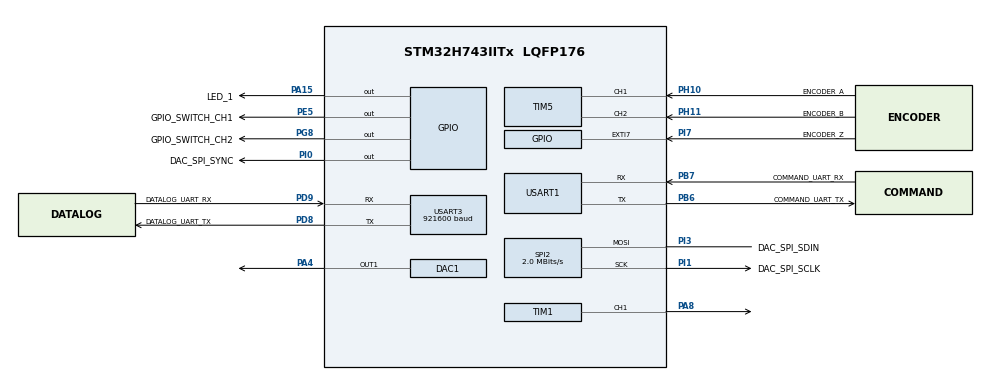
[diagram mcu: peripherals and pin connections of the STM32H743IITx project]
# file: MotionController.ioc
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CORTEX_M7.default_mode_Activation=1
DAC1.DAC_Channel-DAC_OUT1=DAC_CHANNEL_1
Dma.Request0=USART1_TX
Dma.Request1=USART1_RX
Dma.Request2=USART3_TX
Dma.USART1_RX.1.Direction=DMA_PERIPH_TO_MEMORY
Dma.USART1_RX.1.EventEnable=DISABLE
Dma.USART1_RX.1.FIFOMode=DMA_FIFOMODE_DISABLE
Dma.USART1_RX.1.Instance=DMA1_Stream1
Dma.USART1_RX.1.MemDataAlignment=DMA_MDATAALIGN_BYTE
Dma.USART1_RX.1.MemInc=DMA_MINC_ENABLE
Dma.USART1_RX.1.Mode=DMA_NORMAL
Dma.USART1_RX.1.PeriphDataAlignment=DMA_PDATAALIGN_BYTE
Dma.USART1_RX.1.PeriphInc=DMA_PINC_DISABLE
Dma.USART1_RX.1.Polarity=HAL_DMAMUX_REQ_GEN_RISING
Dma.USART1_RX.1.Priority=DMA_PRIORITY_LOW
Dma.USART1_RX.1.RequestNumber=1
Dma.USART1_RX.1.SignalID=NONE
Dma.USART1_RX.1.SyncEnable=DISABLE
Dma.USART1_RX.1.SyncPolarity=HAL_DMAMUX_SYNC_NO_EVENT
Dma.USART1_RX.1.SyncRequestNumber=1
Dma.USART1_RX.1.SyncSignalID=NONE
Dma.USART1_TX.0.Direction=DMA_MEMORY_TO_PERIPH
Dma.USART1_TX.0.EventEnable=DISABLE
Dma.USART1_TX.0.FIFOMode=DMA_FIFOMODE_DISABLE
Dma.USART1_TX.0.Instance=DMA1_Stream0
Dma.USART1_TX.0.MemDataAlignment=DMA_MDATAALIGN_BYTE
Dma.USART1_TX.0.MemInc=DMA_MINC_ENABLE
Dma.USART1_TX.0.Mode=DMA_NORMAL
Dma.USART1_TX.0.PeriphDataAlignment=DMA_PDATAALIGN_BYTE
Dma.USART1_TX.0.PeriphInc=DMA_PINC_DISABLE
Dma.USART1_TX.0.Polarity=HAL_DMAMUX_REQ_GEN_RISING
Dma.USART1_TX.0.Priority=DMA_PRIORITY_LOW
Dma.USART1_TX.0.RequestNumber=1
Dma.USART1_TX.0.SignalID=NONE
Dma.USART1_TX.0.SyncEnable=DISABLE
Dma.USART1_TX.0.SyncPolarity=HAL_DMAMUX_SYNC_NO_EVENT
Dma.USART1_TX.0.SyncRequestNumber=1
Dma.USART1_TX.0.SyncSignalID=NONE
Dma.USART3_TX.2.Direction=DMA_MEMORY_TO_PERIPH
Dma.USART3_TX.2.EventEnable=DISABLE
Dma.USART3_TX.2.FIFOMode=DMA_FIFOMODE_DISABLE
Dma.USART3_TX.2.Instance=DMA1_Stream2
Dma.USART3_TX.2.MemDataAlignment=DMA_MDATAALIGN_BYTE
Dma.USART3_TX.2.MemInc=DMA_MINC_ENABLE
Dma.USART3_TX.2.Mode=DMA_NORMAL
Dma.USART3_TX.2.PeriphDataAlignment=DMA_PDATAALIGN_BYTE
Dma.USART3_TX.2.PeriphInc=DMA_PINC_DISABLE
Dma.USART3_TX.2.Polarity=HAL_DMAMUX_REQ_GEN_RISING
Dma.USART3_TX.2.Priority=DMA_PRIORITY_LOW
Dma.USART3_TX.2.RequestNumber=1
Dma.USART3_TX.2.SignalID=NONE
Dma.USART3_TX.2.SyncEnable=DISABLE
Dma.USART3_TX.2.SyncPolarity=HAL_DMAMUX_SYNC_NO_EVENT
Dma.USART3_TX.2.SyncRequestNumber=1
Dma.USART3_TX.2.SyncSignalID=NONE
Mcu.Family=STM32H7
Mcu.Name=STM32H743IITx
Mcu.Package=LQFP176
Mcu.UserConstants=STATE_TIM_PRESCALER,120-1;STATE_TIM_COUNTER_MAX,100-1;ENCODER_RESOLUTION,(63000 * 1024);PWM_TIM_PRESCALER,12-1;PWM_TIM_COUNTER_MAX,2000-1
NVIC.DMA1_Stream0_IRQn=true\:0\:0\:false\:false\:true\:false\:true\:true
NVIC.DMA1_Stream1_IRQn=true\:0\:0\:false\:false\:true\:false\:true\:true
NVIC.DMA1_Stream2_IRQn=true\:0\:0\:false\:false\:true\:false\:true\:true
NVIC.EXTI9_5_IRQn=true\:0\:0\:false\:false\:true\:true\:true\:true
NVIC.PriorityGroup=NVIC_PRIORITYGROUP_4
NVIC.TIM4_IRQn=true\:0\:0\:false\:false\:true\:true\:true\:true
NVIC.USART1_IRQn=true\:12\:0\:true\:false\:true\:true\:true\:true
NVIC.USART3_IRQn=true\:0\:0\:false\:false\:true\:true\:true\:true
PA13\ (JTMS/SWDIO).Mode=Serial_Wire
PA13\ (JTMS/SWDIO).Signal=DEBUG_JTMS-SWDIO
PA14\ (JTCK/SWCLK).Mode=Serial_Wire
PA14\ (JTCK/SWCLK).Signal=DEBUG_JTCK-SWCLK
PA15\ (JTDI).GPIO_Label=LED_1
PA15\ (JTDI).Signal=GPIO_Output
PA4.Signal=COMP_DAC11_group
PA8.Signal=S_TIM1_CH1
PB6.GPIO_Label=COMMAND_UART_TX
PB6.Mode=Asynchronous
PB6.Signal=USART1_TX
PB7.GPIO_Label=COMMAND_UART_RX
PB7.Mode=Asynchronous
PB7.Signal=USART1_RX
PC6.Signal=S_TIM3_CH1
PC7.Signal=S_TIM3_CH2
PD8.GPIO_Label=DATALOG_UART_TX
PD8.Mode=Asynchronous
PD8.Signal=USART3_TX
PD9.GPIO_Label=DATALOG_UART_RX
PD9.Mode=Asynchronous
PD9.Signal=USART3_RX
PE5.GPIO_Label=GPIO_SWITCH_CH1
PE5.GPIO_PuPd=GPIO_PULLDOWN
PE5.Signal=GPIO_Output
PG8.GPIO_Label=GPIO_SWITCH_CH2
PG8.GPIO_PuPd=GPIO_PULLDOWN
PG8.Signal=GPIO_Output
PH0-OSC_IN\ (PH0).Mode=HSE-External-Oscillator
PH0-OSC_IN\ (PH0).Signal=RCC_OSC_IN
PH1-OSC_OUT\ (PH1).Mode=HSE-External-Oscillator
PH1-OSC_OUT\ (PH1).Signal=RCC_OSC_OUT
PH10.GPIO_Label=ENCODER_A
PH10.Signal=S_TIM5_CH1
PH11.GPIO_Label=ENCODER_B
PH11.Signal=S_TIM5_CH2
PI0.GPIO_Label=DAC_SPI_SYNC
PI0.GPIO_Speed=GPIO_SPEED_FREQ_HIGH
PI0.PinState=GPIO_PIN_SET
PI0.Signal=GPIO_Output
PI1.GPIO_Label=DAC_SPI_SCLK
PI1.Mode=Simplex_Bidirectional_Master
PI1.Signal=SPI2_SCK
PI2.GPIO_Label=DAC_SPI_SDO
PI2.Signal=SPI2_MISO
PI3.GPIO_Label=DAC_SPI_SDIN
PI3.Mode=Simplex_Bidirectional_Master
PI3.Signal=SPI2_MOSI
PI7.GPIO_Label=ENCODER_Z
PI7.GPIO_ModeDefaultEXTI=GPIO_MODE_IT_RISING
PI7.Signal=GPXTI7
ProjectManager.HeapSize=0x200
ProjectManager.StackSize=0x400
ProjectManager.TargetToolchain=STM32CubeIDE
RCC.ADCFreq_Value=129000000
RCC.APB1Freq_Value=120000000
RCC.APB2Freq_Value=120000000
RCC.APB3Freq_Value=120000000
RCC.APB4Freq_Value=120000000
RCC.CortexFreq_Value=480000000
RCC.D1PPRE=RCC_APB3_DIV2
RCC.D2PPRE1=RCC_APB1_DIV2
RCC.D2PPRE2=RCC_APB2_DIV2
RCC.D3PPRE=RCC_APB4_DIV2
RCC.DIVM1=4
RCC.DIVN1=60
RCC.HCLKFreq_Value=240000000
RCC.HPRE=RCC_HCLK_DIV2
RCC.PLLFRACN=0
RCC.PWR_Regulator_Voltage_Scale=PWR_REGULATOR_VOLTAGE_SCALE0
RCC.SPI123CLockSelection=RCC_SPI123CLKSOURCE_CLKP
RCC.SYSCLKFreq_VALUE=480000000
RCC.SYSCLKSource=RCC_SYSCLKSOURCE_PLLCLK
RCC.USBFreq_Value=480000000
SH.COMP_DAC11_group.0=DAC1_OUT1,DAC_OUT1
SH.S_TIM1_CH1.0=TIM1_CH1,PWM Generation1 CH1
SH.S_TIM3_CH1.0=TIM3_CH1
SH.S_TIM3_CH2.0=TIM3_CH2
SH.S_TIM5_CH1.0=TIM5_CH1,Encoder_Interface
SH.S_TIM5_CH2.0=TIM5_CH2,Encoder_Interface
SPI2.BaudRatePrescaler=SPI_BAUDRATEPRESCALER_32
SPI2.CLKPhase=SPI_PHASE_2EDGE
SPI2.CRCCalculation=SPI_CRCCALCULATION_DISABLE
SPI2.CalculateBaudRate=2.0 MBits/s
SPI2.DataSize=SPI_DATASIZE_8BIT
SPI2.Direction=SPI_DIRECTION_1LINE
SPI2.Mode=SPI_MODE_MASTER
SPI2.VirtualType=VM_MASTER
TIM1.Channel-PWM\ Generation1\ CH1=TIM_CHANNEL_1
TIM1.Period=PWM_TIM_COUNTER_MAX
TIM1.Prescaler=PWM_TIM_PRESCALER
TIM1.Pulse-PWM\ Generation1\ CH1=(PWM_TIM_COUNTER_MAX+1)/2
TIM4.Period=STATE_TIM_COUNTER_MAX
TIM4.Prescaler=STATE_TIM_PRESCALER
TIM5.AutoReloadPreload=TIM_AUTORELOAD_PRELOAD_DISABLE
TIM5.ClockDivision=TIM_CLOCKDIVISION_DIV1
TIM5.EncoderMode=TIM_ENCODERMODE_TI12
TIM5.IC1Filter=2
TIM5.IC2Filter=2
TIM5.Period=ENCODER_RESOLUTION-1
USART1.VirtualMode-Asynchronous=VM_ASYNC
USART3.BaudRate=921600
USART3.VirtualMode-Asynchronous=VM_ASYNC
VP_TIM1_VS_ClockSourceINT.Mode=Internal
VP_TIM4_VS_ClockSourceINT.Mode=Internal
board=custom

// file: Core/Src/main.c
/* USER CODE BEGIN Header */
/**
 ******************************************************************************
 * @file           : main.c
 * @brief          : Main program body
 ******************************************************************************
 * @attention
 *
 * Copyright (c) 2024 STMicroelectronics.
 * All rights reserved.
 *
 * This software is licensed under terms that can be found in the LICENSE file
 * in the root directory of this software component.
 * If no LICENSE file comes with this software, it is provided AS-IS.
 *
 ******************************************************************************
 */
/* USER CODE END Header */
#include "main.h"
#include "dac.h"
#include "dma.h"
#include "spi.h"
#include "tim.h"
#include "usart.h"
#include "gpio.h"

/* USER CODE BEGIN Includes */
#include "main_app.h"
/* USER CODE END Includes */

void SystemClock_Config(void);
void PeriphCommonClock_Config(void);
static void MPU_Config(void);

int main(void)
{

  /* MPU Configuration--------------------------------------------------------*/
  MPU_Config();

  /* MCU Configuration--------------------------------------------------------*/

  /* Reset of all peripherals, Initializes the Flash interface and the Systick. */
  HAL_Init();

  /* Configure the system clock */
  SystemClock_Config();

/* Configure the peripherals common clocks */
  PeriphCommonClock_Config();

  /* Initialize all configured peripherals */
  MX_GPIO_Init();
  MX_DMA_Init();
  MX_USART3_UART_Init();
  MX_USART1_UART_Init();
  MX_DAC1_Init();
  MX_TIM4_Init();
  MX_TIM5_Init();
  MX_SPI2_Init();
  MX_TIM1_Init();
  /* USER CODE BEGIN 2 */
    Init_App_Functions();
    // Set_PWM_Value(1500);
  /* USER CODE END 2 */

  /* Infinite loop */
  /* USER CODE BEGIN WHILE */
    while (1) {
        Run_App_Functions();

    /* USER CODE END WHILE */

    }
}

void SystemClock_Config(void)
{
  RCC_OscInitTypeDef RCC_OscInitStruct = {0};
  RCC_ClkInitTypeDef RCC_ClkInitStruct = {0};

  /** Supply configuration update enable
  */
  HAL_PWREx_ConfigSupply(PWR_LDO_SUPPLY);

  /** Configure the main internal regulator output voltage
  */
  __HAL_PWR_VOLTAGESCALING_CONFIG(PWR_REGULATOR_VOLTAGE_SCALE1);

  while(!__HAL_PWR_GET_FLAG(PWR_FLAG_VOSRDY)) {}

  __HAL_RCC_SYSCFG_CLK_ENABLE();
  __HAL_PWR_VOLTAGESCALING_CONFIG(PWR_REGULATOR_VOLTAGE_SCALE0);

  while(!__HAL_PWR_GET_FLAG(PWR_FLAG_VOSRDY)) {}

  /** Initializes the RCC Oscillators according to the specified parameters
  * in the RCC_OscInitTypeDef structure.
  */
  RCC_OscInitStruct.OscillatorType = RCC_OSCILLATORTYPE_HSI;
  RCC_OscInitStruct.HSIState = RCC_HSI_DIV1;
  RCC_OscInitStruct.HSICalibrationValue = RCC_HSICALIBRATION_DEFAULT;
  RCC_OscInitStruct.PLL.PLLState = RCC_PLL_ON;
  RCC_OscInitStruct.PLL.PLLSource = RCC_PLLSOURCE_HSI;
  RCC_OscInitStruct.PLL.PLLM = 4;
  RCC_OscInitStruct.PLL.PLLN = 60;
  RCC_OscInitStruct.PLL.PLLP = 2;
  RCC_OscInitStruct.PLL.PLLQ = 2;
  RCC_OscInitStruct.PLL.PLLR = 2;
  RCC_OscInitStruct.PLL.PLLRGE = RCC_PLL1VCIRANGE_3;
  RCC_OscInitStruct.PLL.PLLVCOSEL = RCC_PLL1VCOWIDE;
  RCC_OscInitStruct.PLL.PLLFRACN = 0;
  if (HAL_RCC_OscConfig(&RCC_OscInitStruct) != HAL_OK)
  {
    Error_Handler();
  }

  /** Initializes the CPU, AHB and APB buses clocks
  */
  RCC_ClkInitStruct.ClockType = RCC_CLOCKTYPE_HCLK|RCC_CLOCKTYPE_SYSCLK
                              |RCC_CLOCKTYPE_PCLK1|RCC_CLOCKTYPE_PCLK2
                              |RCC_CLOCKTYPE_D3PCLK1|RCC_CLOCKTYPE_D1PCLK1;
  RCC_ClkInitStruct.SYSCLKSource = RCC_SYSCLKSOURCE_PLLCLK;
  RCC_ClkInitStruct.SYSCLKDivider = RCC_SYSCLK_DIV1;
  RCC_ClkInitStruct.AHBCLKDivider = RCC_HCLK_DIV2;
  RCC_ClkInitStruct.APB3CLKDivider = RCC_APB3_DIV2;
  RCC_ClkInitStruct.APB1CLKDivider = RCC_APB1_DIV2;
  RCC_ClkInitStruct.APB2CLKDivider = RCC_APB2_DIV2;
  RCC_ClkInitStruct.APB4CLKDivider = RCC_APB4_DIV2;

  if (HAL_RCC_ClockConfig(&RCC_ClkInitStruct, FLASH_LATENCY_4) != HAL_OK)
  {
    Error_Handler();
  }
}

void PeriphCommonClock_Config(void)
{
  RCC_PeriphCLKInitTypeDef PeriphClkInitStruct = {0};

  /** Initializes the peripherals clock
  */
  PeriphClkInitStruct.PeriphClockSelection = RCC_PERIPHCLK_CKPER;
  PeriphClkInitStruct.CkperClockSelection = RCC_CLKPSOURCE_HSI;
  if (HAL_RCCEx_PeriphCLKConfig(&PeriphClkInitStruct) != HAL_OK)
  {
    Error_Handler();
  }
}

 /* MPU Configuration */

void MPU_Config(void)
{
  MPU_Region_InitTypeDef MPU_InitStruct = {0};

  /* Disables the MPU */
  HAL_MPU_Disable();

  /** Initializes and configures the Region and the memory to be protected
  */
  MPU_InitStruct.Enable = MPU_REGION_ENABLE;
  MPU_InitStruct.Number = MPU_REGION_NUMBER0;
  MPU_InitStruct.BaseAddress = 0x0;
  MPU_InitStruct.Size = MPU_REGION_SIZE_4GB;
  MPU_InitStruct.SubRegionDisable = 0x87;
  MPU_InitStruct.TypeExtField = MPU_TEX_LEVEL0;
  MPU_InitStruct.AccessPermission = MPU_REGION_NO_ACCESS;
  MPU_InitStruct.DisableExec = MPU_INSTRUCTION_ACCESS_DISABLE;
  MPU_InitStruct.IsShareable = MPU_ACCESS_SHAREABLE;
  MPU_InitStruct.IsCacheable = MPU_ACCESS_NOT_CACHEABLE;
  MPU_InitStruct.IsBufferable = MPU_ACCESS_NOT_BUFFERABLE;

  HAL_MPU_ConfigRegion(&MPU_InitStruct);
  /* Enables the MPU */
  HAL_MPU_Enable(MPU_PRIVILEGED_DEFAULT);

}

void Error_Handler(void)
{
    __disable_irq();
    while (1) {
    }
}
